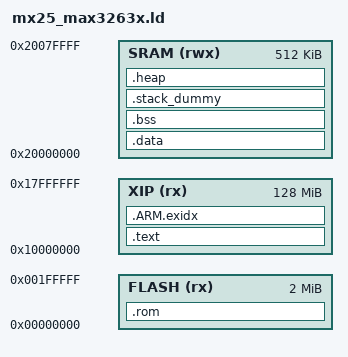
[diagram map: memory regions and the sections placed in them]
/*******************************************************************************
 * Copyright (C) 2016 Maxim Integrated Products, Inc., All Rights Reserved.
 *
 * Permission is hereby granted, free of charge, to any person obtaining a
 * copy of this software and associated documentation files (the "Software"),
 * to deal in the Software without restriction, including without limitation
 * the rights to use, copy, modify, merge, publish, distribute, sublicense,
 * and/or sell copies of the Software, and to permit persons to whom the
 * Software is furnished to do so, subject to the following conditions:
 *
 * The above copyright notice and this permission notice shall be included
 * in all copies or substantial portions of the Software.
 *
 * THE SOFTWARE IS PROVIDED "AS IS", WITHOUT WARRANTY OF ANY KIND, EXPRESS
 * OR IMPLIED, INCLUDING BUT NOT LIMITED TO THE WARRANTIES OF
 * MERCHANTABILITY, FITNESS FOR A PARTICULAR PURPOSE AND NONINFRINGEMENT.
 * IN NO EVENT SHALL MAXIM INTEGRATED BE LIABLE FOR ANY CLAIM, DAMAGES
 * OR OTHER LIABILITY, WHETHER IN AN ACTION OF CONTRACT, TORT OR OTHERWISE,
 * ARISING FROM, OUT OF OR IN CONNECTION WITH THE SOFTWARE OR THE USE OR
 * OTHER DEALINGS IN THE SOFTWARE.
 *
 * Except as contained in this notice, the name of Maxim Integrated
 * Products, Inc. shall not be used except as stated in the Maxim Integrated
 * Products, Inc. Branding Policy.
 *
 * The mere transfer of this software does not imply any licenses
 * of trade secrets, proprietary technology, copyrights, patents,
 * trademarks, maskwork rights, or any other form of intellectual
 * property whatsoever. Maxim Integrated Products, Inc. retains all
 * ownership rights.
 *
 * $Date: 2016-03-11 11:46:02 -0600 (Fri, 11 Mar 2016) $ 
 * $Revision: 21838 $
 *
 ******************************************************************************/

MEMORY
{
    FLASH (rx) : ORIGIN = 0x00000000, LENGTH = 0x00200000 /* start from 0x0, fullsize flash, 2M */
    SRAM (rwx) : ORIGIN = 0x20000000, LENGTH = 0x00080000 /* full-size SRAM, 512K */
    XIP (rx)   : ORIGIN = 0x10000000, LENGTH = 0x08000000 /* 128 Mb SPIX */
}

SECTIONS
{
    .rom :
    {
        KEEP(*(.rom_vector))
        *(.rom_handlers*)
    } > FLASH

    .text :
    {
        _text = .;
	KEEP(*(.isr_vector))
        *(.text*)    /* program code */
        *(.rodata*)  /* read-only data: "const" variable */
    } > XIP

    /* it's used for C++ exception handling      */
    /* we need to keep this to avoid overlapping */
    .ARM.exidx :
    {
        __exidx_start = .;
        *(.ARM.exidx*)
        __exidx_end = .;
    } > XIP

    _etext = ALIGN(., 4);

    .data : AT(_etext)
    {
        _data = .;
        *(.data*)    /*read-write initialized data: initialized global variable*/
        _edata = ALIGN(., 4);
    } > SRAM

    .bss :
    {
	. = ALIGN(4);
        _bss = .; 
        *(.bss*)     /*read-write zero initialized data: uninitialzed global variable*/
        *(COMMON)
	_ebss = ALIGN(., 4);
    } > SRAM

    /* Set stack top to end of RAM, and stack limit move down by
     * size of stack_dummy section */
     __StackTop = ORIGIN(SRAM) + LENGTH(SRAM);
     __StackLimit = __StackTop - SIZEOF(.stack_dummy);

    /* .stack_dummy section doesn't contains any symbols. It is only
     * used for linker to calculate size of stack sections, and assign
     * values to stack symbols later */
    .stack_dummy (COPY):
    {
        *(.stack*)
    } > SRAM

    .heap (COPY):
    {
	. = ALIGN(4);
	*(.heap*)
	__HeapLimit = ABSOLUTE(__StackLimit);
    } > SRAM

    PROVIDE(__stack = __StackTop);

    /* Check if data + heap + stack exceeds RAM limit */
    ASSERT(__StackLimit >= _ebss, "region RAM overflowed with stack")
}
